VERSION ""

NS_ :

BS_:

BU_:

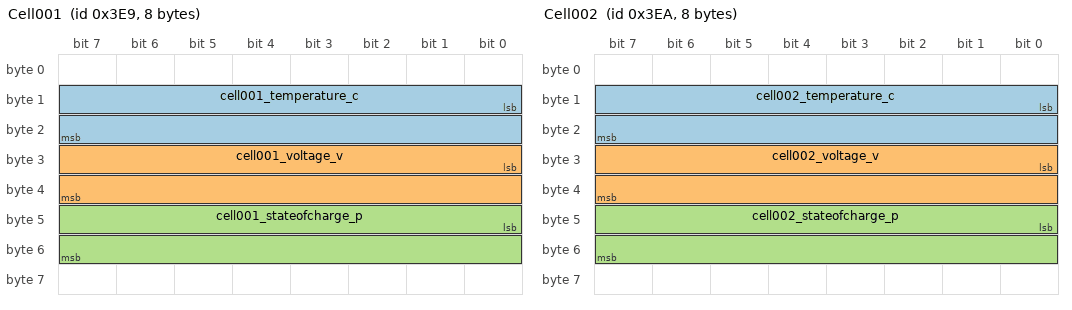
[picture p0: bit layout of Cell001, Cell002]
BO_ 1001 Cell001: 8 Vector__XXX
 SG_ cell001_temperature_c :	 8|16@1+ (0.5,-40) [-40|87.5] "degC" Vector__XXX
 SG_ cell001_voltage_v :        24|16@1+ (0.25,-100.0) [-100|1000] "v" Vector__XXX
 SG_ cell001_stateofcharge_p :  40|16@1+ (0.01,0.0) [0|1] "SoC" Vector__XXX

BO_ 1002 Cell002: 8 Vector__XXX
 SG_ cell002_temperature_c :	 8|16@1+ (0.5,-40) [-40|87.5] "degC" Vector__XXX
 SG_ cell002_voltage_v :        24|16@1+ (0.25,-100.0) [-100|1000] "v" Vector__XXX
 SG_ cell002_stateofcharge_p :  40|16@1+ (0.01,0.0) [0|1] "SoC" Vector__XXX

BA_DEF_ BO_  "GenMsgCycleTime" INT 0 10000;
BA_DEF_DEF_  "GenMsgCycleTime" 0;

BA_ "GenMsgCycleTime" BO_ 1000 500;
